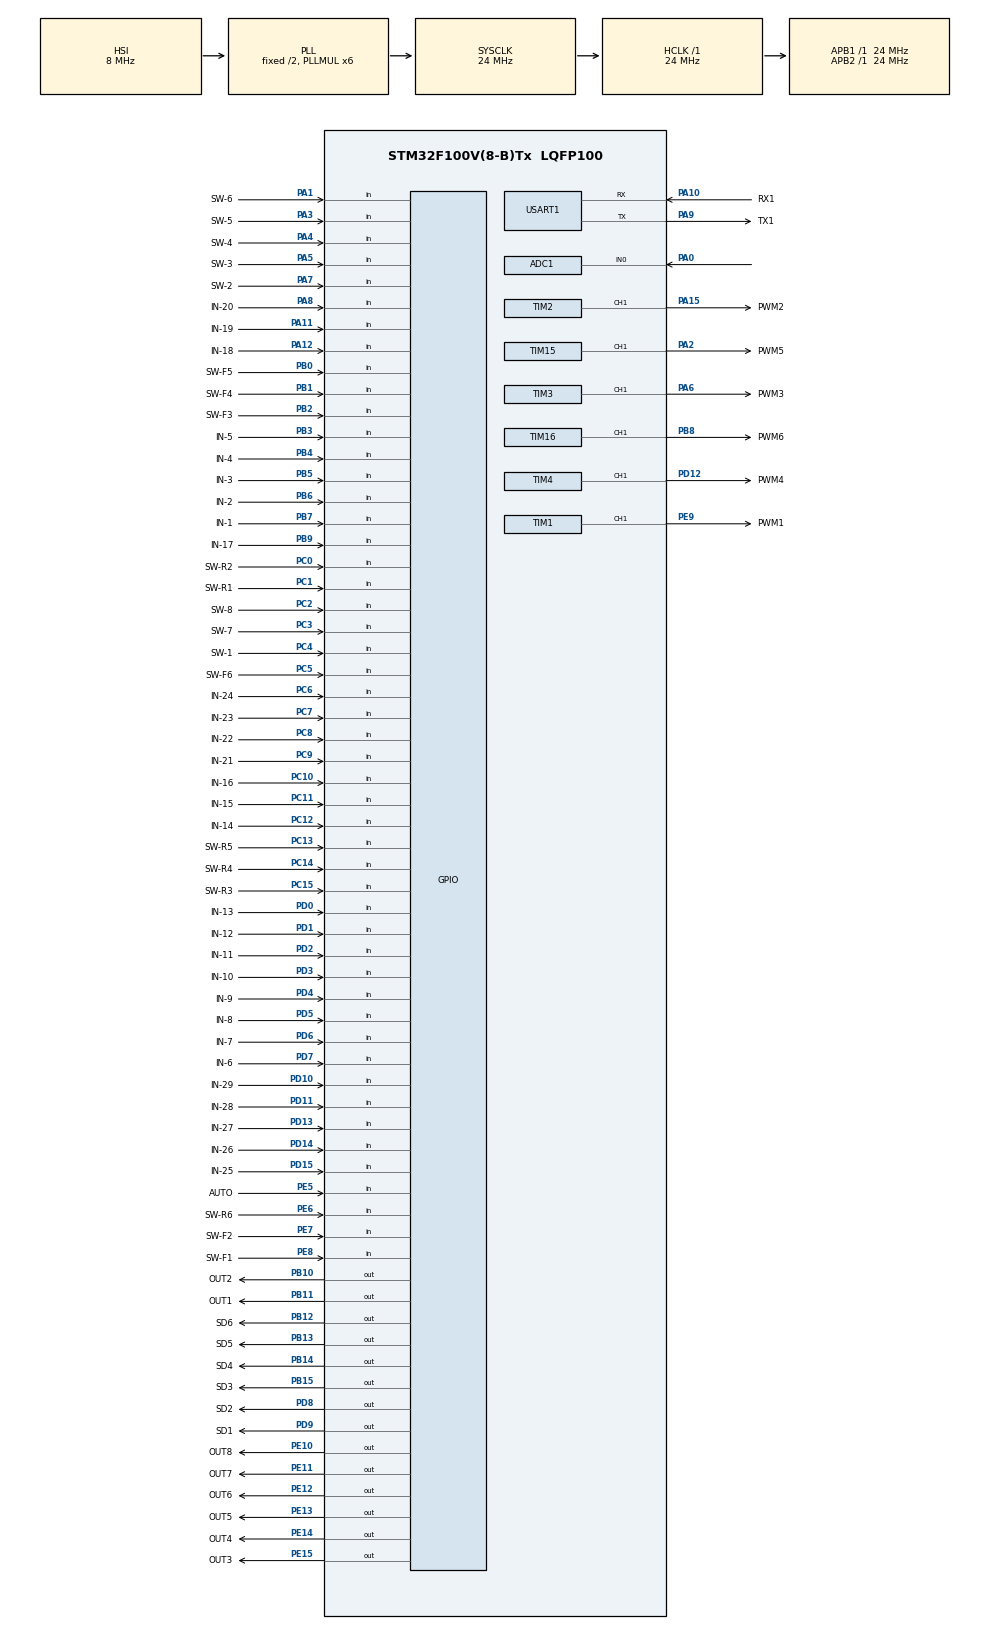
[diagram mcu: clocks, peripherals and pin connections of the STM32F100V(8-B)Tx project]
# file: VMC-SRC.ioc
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ADC1.Channel-0\#ChannelRegularConversion=ADC_CHANNEL_0
ADC1.NbrOfConversionFlag=1
ADC1.Rank-0\#ChannelRegularConversion=1
ADC1.SamplingTime-0\#ChannelRegularConversion=ADC_SAMPLETIME_1CYCLE_5
ADC1.master=1
Mcu.Family=STM32F1
Mcu.Name=STM32F100V(8-B)Tx
Mcu.Package=LQFP100
NVIC.PriorityGroup=NVIC_PRIORITYGROUP_4
NVIC.USART1_IRQn=true\:0\:0\:false\:false\:true\:true
PA0-WKUP.Signal=ADCx_IN0
PA1.GPIO_Label=SW-6
PA1.Signal=GPIO_Input
PA10.GPIO_Label=RX1
PA10.Mode=Asynchronous
PA10.Signal=USART1_RX
PA11.GPIO_Label=IN-19
PA11.Signal=GPIO_Input
PA12.GPIO_Label=IN-18
PA12.Signal=GPIO_Input
PA13.Mode=Serial_Wire
PA13.Signal=SYS_JTMS-SWDIO
PA14.Mode=Serial_Wire
PA14.Signal=SYS_JTCK-SWCLK
PA15.GPIO_Label=PWM2
PA15.Signal=S_TIM2_CH1_ETR
PA2.GPIO_Label=PWM5
PA2.Signal=S_TIM15_CH1
PA3.GPIO_Label=SW-5
PA3.Signal=GPIO_Input
PA4.GPIO_Label=SW-4
PA4.Signal=GPIO_Input
PA5.GPIO_Label=SW-3
PA5.Signal=GPIO_Input
PA6.GPIO_Label=PWM3
PA6.Signal=S_TIM3_CH1
PA7.GPIO_Label=SW-2
PA7.Signal=GPIO_Input
PA8.GPIO_Label=IN-20
PA8.Signal=GPIO_Input
PA9.GPIO_Label=TX1
PA9.Mode=Asynchronous
PA9.Signal=USART1_TX
PB0.GPIO_Label=SW-F5
PB0.Signal=GPIO_Input
PB1.GPIO_Label=SW-F4
PB1.Signal=GPIO_Input
PB10.GPIO_Label=OUT2
PB10.Signal=GPIO_Output
PB11.GPIO_Label=OUT1
PB11.Signal=GPIO_Output
PB12.GPIO_Label=SD6
PB12.Signal=GPIO_Output
PB13.GPIO_Label=SD5
PB13.Signal=GPIO_Output
PB14.GPIO_Label=SD4
PB14.Signal=GPIO_Output
PB15.GPIO_Label=SD3
PB15.Signal=GPIO_Output
PB2.GPIO_Label=SW-F3
PB2.Signal=GPIO_Input
PB3.GPIO_Label=IN-5
PB3.Signal=GPIO_Input
PB4.GPIO_Label=IN-4
PB4.Signal=GPIO_Input
PB5.GPIO_Label=IN-3
PB5.Signal=GPIO_Input
PB6.GPIO_Label=IN-2
PB6.Signal=GPIO_Input
PB7.GPIO_Label=IN-1
PB7.Signal=GPIO_Input
PB8.GPIO_Label=PWM6
PB8.Signal=S_TIM16_CH1
PB9.GPIO_Label=IN-17
PB9.Signal=GPIO_Input
PC0.GPIO_Label=SW-R2
PC0.Signal=GPIO_Input
PC1.GPIO_Label=SW-R1
PC1.Signal=GPIO_Input
PC10.GPIO_Label=IN-16
PC10.Signal=GPIO_Input
PC11.GPIO_Label=IN-15
PC11.Signal=GPIO_Input
PC12.GPIO_Label=IN-14
PC12.Signal=GPIO_Input
PC13-TAMPER-RTC.GPIO_Label=SW-R5
PC13-TAMPER-RTC.Signal=GPIO_Input
PC14-OSC32_IN.GPIO_Label=SW-R4
PC14-OSC32_IN.Signal=GPIO_Input
PC15-OSC32_OUT.GPIO_Label=SW-R3
PC15-OSC32_OUT.Signal=GPIO_Input
PC2.GPIO_Label=SW-8
PC2.Signal=GPIO_Input
PC3.GPIO_Label=SW-7
PC3.Signal=GPIO_Input
PC4.GPIO_Label=SW-1
PC4.Signal=GPIO_Input
PC5.GPIO_Label=SW-F6
PC5.Signal=GPIO_Input
PC6.GPIO_Label=IN-24
PC6.Signal=GPIO_Input
PC7.GPIO_Label=IN-23
PC7.Signal=GPIO_Input
PC8.GPIO_Label=IN-22
PC8.Signal=GPIO_Input
PC9.GPIO_Label=IN-21
PC9.Signal=GPIO_Input
PD0.GPIO_Label=IN-13
PD0.Signal=GPIO_Input
PD1.GPIO_Label=IN-12
PD1.Signal=GPIO_Input
PD10.GPIO_Label=IN-29
PD10.Signal=GPIO_Input
PD11.GPIO_Label=IN-28
PD11.Signal=GPIO_Input
PD12.GPIO_Label=PWM4
PD12.Signal=S_TIM4_CH1
PD13.GPIO_Label=IN-27
PD13.Signal=GPIO_Input
PD14.GPIO_Label=IN-26
PD14.Signal=GPIO_Input
PD15.GPIO_Label=IN-25
PD15.Signal=GPIO_Input
PD2.GPIO_Label=IN-11
PD2.Signal=GPIO_Input
PD3.GPIO_Label=IN-10
PD3.Signal=GPIO_Input
PD4.GPIO_Label=IN-9
PD4.Signal=GPIO_Input
PD5.GPIO_Label=IN-8
PD5.Signal=GPIO_Input
PD6.GPIO_Label=IN-7
PD6.Signal=GPIO_Input
PD7.GPIO_Label=IN-6
PD7.Signal=GPIO_Input
PD8.GPIO_Label=SD2
PD8.Signal=GPIO_Output
PD9.GPIO_Label=SD1
PD9.Signal=GPIO_Output
PE10.GPIO_Label=OUT8
PE10.Signal=GPIO_Output
PE11.GPIO_Label=OUT7
PE11.Signal=GPIO_Output
PE12.GPIO_Label=OUT6
PE12.Signal=GPIO_Output
PE13.GPIO_Label=OUT5
PE13.Signal=GPIO_Output
PE14.GPIO_Label=OUT4
PE14.Signal=GPIO_Output
PE15.GPIO_Label=OUT3
PE15.Signal=GPIO_Output
PE5.GPIO_Label=AUTO
PE5.Signal=GPIO_Input
PE6.GPIO_Label=SW-R6
PE6.Signal=GPIO_Input
PE7.GPIO_Label=SW-F2
PE7.Signal=GPIO_Input
PE8.GPIO_Label=SW-F1
PE8.Signal=GPIO_Input
PE9.GPIO_Label=PWM1
PE9.Signal=S_TIM1_CH1
ProjectManager.HeapSize=0x200
ProjectManager.StackSize=0x400
ProjectManager.TargetToolchain=MDK-ARM V5
RCC.AHBFreq_Value=24000000
RCC.APB1Freq_Value=24000000
RCC.APB1TimFreq_Value=24000000
RCC.APB2Freq_Value=24000000
RCC.APB2TimFreq_Value=24000000
RCC.HCLKFreq_Value=24000000
RCC.PLLMUL=RCC_PLL_MUL6
RCC.SYSCLKFreq_VALUE=24000000
RCC.SYSCLKSource=RCC_SYSCLKSOURCE_PLLCLK
SH.ADCx_IN0.0=ADC1_IN0,IN0
SH.S_TIM15_CH1.0=TIM15_CH1,PWM Generation1 CH1
SH.S_TIM16_CH1.0=TIM16_CH1,PWM Generation1 CH1
SH.S_TIM1_CH1.0=TIM1_CH1,PWM Generation1 CH1
SH.S_TIM2_CH1_ETR.0=TIM2_CH1,PWM Generation1 CH1
SH.S_TIM3_CH1.0=TIM3_CH1,PWM Generation1 CH1
SH.S_TIM4_CH1.0=TIM4_CH1,PWM Generation1 CH1
TIM1.Channel-PWM\ Generation1\ CH1=TIM_CHANNEL_1
TIM1.Period=49
TIM1.Prescaler=23
TIM1.Pulse-PWM\ Generation1\ CH1=45
TIM15.Channel-PWM\ Generation1\ CH1=TIM_CHANNEL_1
TIM16.Channel=TIM_CHANNEL_1
TIM2.Channel-PWM\ Generation1\ CH1=TIM_CHANNEL_1
TIM3.Channel-PWM\ Generation1\ CH1=TIM_CHANNEL_1
TIM4.Channel-PWM\ Generation1\ CH1=TIM_CHANNEL_1
USART1.VirtualMode=VM_ASYNC
VP_TIM16_VS_ClockSourceINT.Mode=Enable_Timer
VP_TIM3_VS_ClockSourceINT.Mode=Internal
board=VMC-SRC

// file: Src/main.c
/**
  ******************************************************************************
  * @file           : main.c
  * @brief          : Main program body
  ******************************************************************************
  ** This notice applies to any and all portions of this file
  * that are not between comment pairs USER CODE BEGIN and
  * USER CODE END. Other portions of this file, whether
  * inserted by the user or by software development tools
  * are owned by their respective copyright owners.
  *
  * COPYRIGHT(c) 2018 STMicroelectronics
  *
  * Redistribution and use in source and binary forms, with or without modification,
  * are permitted provided that the following conditions are met:
  *   1. Redistributions of source code must retain the above copyright notice,
  *      this list of conditions and the following disclaimer.
  *   2. Redistributions in binary form must reproduce the above copyright notice,
  *      this list of conditions and the following disclaimer in the documentation
  *      and/or other materials provided with the distribution.
  *   3. Neither the name of STMicroelectronics nor the names of its contributors
  *      may be used to endorse or promote products derived from this software
  *      without specific prior written permission.
  *
  * THIS SOFTWARE IS PROVIDED BY THE COPYRIGHT HOLDERS AND CONTRIBUTORS "AS IS"
  * AND ANY EXPRESS OR IMPLIED WARRANTIES, INCLUDING, BUT NOT LIMITED TO, THE
  * IMPLIED WARRANTIES OF MERCHANTABILITY AND FITNESS FOR A PARTICULAR PURPOSE ARE
  * DISCLAIMED. IN NO EVENT SHALL THE COPYRIGHT HOLDER OR CONTRIBUTORS BE LIABLE
  * FOR ANY DIRECT, INDIRECT, INCIDENTAL, SPECIAL, EXEMPLARY, OR CONSEQUENTIAL
  * DAMAGES (INCLUDING, BUT NOT LIMITED TO, PROCUREMENT OF SUBSTITUTE GOODS OR
  * SERVICES; LOSS OF USE, DATA, OR PROFITS; OR BUSINESS INTERRUPTION) HOWEVER
  * CAUSED AND ON ANY THEORY OF LIABILITY, WHETHER IN CONTRACT, STRICT LIABILITY,
  * OR TORT (INCLUDING NEGLIGENCE OR OTHERWISE) ARISING IN ANY WAY OUT OF THE USE
  * OF THIS SOFTWARE, EVEN IF ADVISED OF THE POSSIBILITY OF SUCH DAMAGE.
  *
  ******************************************************************************
  */
#include "main.h"
#include "stm32f1xx_hal.h"

/* USER CODE BEGIN Includes */
#include "C:\Users\TheVeganElectrolance\Documents\Electrolance Company\Projects\04042018-JAAVIN-VMC\VMC-SRC\MDK-ARM\appGPIO.h"
/* USER CODE END Includes */

ADC_HandleTypeDef hadc1;

TIM_HandleTypeDef htim1;
TIM_HandleTypeDef htim2;
TIM_HandleTypeDef htim3;
TIM_HandleTypeDef htim4;
TIM_HandleTypeDef htim15;
TIM_HandleTypeDef htim16;

UART_HandleTypeDef huart1;

/* USER CODE BEGIN PV */
/* Private variables ---------------------------------------------------------*/
extern void (* fparr[8]) ();
uint32_t  manualSWV =0xFFFFFFFF;
uint8_t buffer[30];
uint8_t data;
uint8_t indexA = 0;
uint8_t final_pos = 0;
_Bool processData = 0;
//extern void readmanualSW();
//extern void trigmanualSW();
/* USER CODE END PV */

void SystemClock_Config(void);
static void MX_GPIO_Init(void);
static void MX_ADC1_Init(void);
static void MX_TIM1_Init(void);
static void MX_TIM2_Init(void);
static void MX_TIM3_Init(void);
static void MX_TIM4_Init(void);
static void MX_TIM15_Init(void);
static void MX_TIM16_Init(void);
static void MX_USART1_UART_Init(void);

void HAL_TIM_MspPostInit(TIM_HandleTypeDef *htim);

/* USER CODE BEGIN PFP */
/* Private function prototypes -----------------------------------------------*/

/* USER CODE END PFP */

int main(void)
{
  /* USER CODE BEGIN 1 */
	indexA = 0x00;
  /* USER CODE END 1 */

  /* MCU Configuration----------------------------------------------------------*/

  /* Reset of all peripherals, Initializes the Flash interface and the Systick. */
  HAL_Init();

  /* Configure the system clock */
  SystemClock_Config();

  /* Initialize all configured peripherals */
  MX_GPIO_Init();
  MX_ADC1_Init();
  MX_TIM1_Init();
  MX_TIM2_Init();
  MX_TIM3_Init();
  MX_TIM4_Init();
  MX_TIM15_Init();
  MX_TIM16_Init();
  MX_USART1_UART_Init();
  /* USER CODE BEGIN 2 */
	_Bool Auto = 0x00;
	_Bool autoButton;
	__HAL_UART_ENABLE_IT(&huart1, UART_IT_RXNE);
	HAL_UART_Receive_IT(&huart1,&data, 1);// enable UART interupt
  /* USER CODE END 2 */

  /* Infinite loop */
  /* USER CODE BEGIN WHILE */
  while (1)
  {

		autoButton = HAL_GPIO_ReadPin(AUTO_GPIO_Port,AUTO_Pin);
		if(HAL_GPIO_ReadPin(AUTO_GPIO_Port,AUTO_Pin))
		{
			Auto = 0x01;
		}
		else
		{
			Auto = 0x00;
			//Read all the switch
			readmanualSW();
			//Trigger Function.
			trigmanualSW();
		}

		//HAL_GPIO_TogglePin(OUT1_GPIO_Port,OUT1_Pin);
		//HAL_Delay(1000);
		//RELAY8_ON();
		HAL_Delay(1000);
		//RELAY8_OFF();
		//HAL_GPIO_WritePin(OUT1_GPIO_Port,OUT1_Pin, GPIO_PIN_SET
  /* USER CODE END WHILE */

  /* USER CODE BEGIN 3 */

//			for(uint8_t x =0; x<16;x++)
//      {
//				(*fparr[x])();
//				HAL_Delay(500);
//      }

		if(processData)
		{
			// DO all the check.
			processData = 0;
			//on the interupt receive
			switch (buffer[3])
      {
      	case 0x23: //relay turn
					if((buffer[4] + buffer[5]) == (uint8_t) 0x01) // Relay 1 OFF
						RELAY1_OFF();
					else if ((buffer[4] + buffer[5]) == (uint8_t)0x02)
					{
						RELAY1_ON();
					}

					if((buffer[4] + buffer[5]) == (uint8_t) 0x02) // Relay 2 OFF
						RELAY2_OFF();
					else if ((buffer[4] + buffer[5]) == (uint8_t)0x03)
					{
						RELAY2_ON();
					}

					if((buffer[4] + buffer[5]) == (uint8_t) 0x03) // Relay 3 OFF
						RELAY3_OFF();
					else if ((buffer[4] + buffer[5]) == (uint8_t)0x04)
					{
						RELAY3_ON();
					}

					if((buffer[4] + buffer[5]) == (uint8_t) 0x04) // Relay 4 OFF
						RELAY4_OFF();
					else if ((buffer[4] + buffer[5]) == (uint8_t)0x05)
					{
						RELAY4_ON();
					}

					if((buffer[4] + buffer[5]) == (uint8_t) 0x05) // Relay 5 OFF
						RELAY5_OFF();
					else if ((buffer[4] + buffer[5]) == (uint8_t)0x06)
					{
						RELAY5_ON();
					}

					if((buffer[4] + buffer[5]) == (uint8_t) 0x06) // Relay 6 OFF
						RELAY6_OFF();
					else if ((buffer[4] + buffer[5]) == (uint8_t)0x07)
					{
						RELAY6_ON();
					}

					if((buffer[4] + buffer[5]) == (uint8_t) 0x07) // Relay 7 OFF
						RELAY7_OFF();
					else if ((buffer[4] + buffer[5]) == (uint8_t)0x08)
					{
						RELAY7_ON();
					}

					if((buffer[4] + buffer[5]) == (uint8_t) 0x08) // Relay 8 OFF
						RELAY8_OFF();
					else if ((buffer[4] + buffer[5]) == (uint8_t)0x09)
					{
						RELAY8_ON();
					}

					HAL_UART_Receive_IT(&huart1,&data, 1);
      		break;
      	//case:
      		//break;
      	default:
					//HAL_UART_Receive_IT(&huart1,&data, 1);
      		break;

      }
		}

	}
  /* USER CODE END 3 */

}

void SystemClock_Config(void)
{

  RCC_OscInitTypeDef RCC_OscInitStruct;
  RCC_ClkInitTypeDef RCC_ClkInitStruct;
  RCC_PeriphCLKInitTypeDef PeriphClkInit;

    /**Initializes the CPU, AHB and APB busses clocks
    */
  RCC_OscInitStruct.OscillatorType = RCC_OSCILLATORTYPE_HSI;
  RCC_OscInitStruct.HSIState = RCC_HSI_ON;
  RCC_OscInitStruct.HSICalibrationValue = 16;
  RCC_OscInitStruct.PLL.PLLState = RCC_PLL_ON;
  RCC_OscInitStruct.PLL.PLLSource = RCC_PLLSOURCE_HSI_DIV2;
  RCC_OscInitStruct.PLL.PLLMUL = RCC_PLL_MUL6;
  if (HAL_RCC_OscConfig(&RCC_OscInitStruct) != HAL_OK)
  {
    _Error_Handler(__FILE__, __LINE__);
  }

    /**Initializes the CPU, AHB and APB busses clocks
    */
  RCC_ClkInitStruct.ClockType = RCC_CLOCKTYPE_HCLK|RCC_CLOCKTYPE_SYSCLK
                              |RCC_CLOCKTYPE_PCLK1|RCC_CLOCKTYPE_PCLK2;
  RCC_ClkInitStruct.SYSCLKSource = RCC_SYSCLKSOURCE_PLLCLK;
  RCC_ClkInitStruct.AHBCLKDivider = RCC_SYSCLK_DIV1;
  RCC_ClkInitStruct.APB1CLKDivider = RCC_HCLK_DIV1;
  RCC_ClkInitStruct.APB2CLKDivider = RCC_HCLK_DIV1;

  if (HAL_RCC_ClockConfig(&RCC_ClkInitStruct, FLASH_LATENCY_0) != HAL_OK)
  {
    _Error_Handler(__FILE__, __LINE__);
  }

  PeriphClkInit.PeriphClockSelection = RCC_PERIPHCLK_ADC;
  PeriphClkInit.AdcClockSelection = RCC_ADCPCLK2_DIV2;
  if (HAL_RCCEx_PeriphCLKConfig(&PeriphClkInit) != HAL_OK)
  {
    _Error_Handler(__FILE__, __LINE__);
  }

    /**Configure the Systick interrupt time
    */
  HAL_SYSTICK_Config(HAL_RCC_GetHCLKFreq()/1000);

    /**Configure the Systick
    */
  HAL_SYSTICK_CLKSourceConfig(SYSTICK_CLKSOURCE_HCLK);

  /* SysTick_IRQn interrupt configuration */
  HAL_NVIC_SetPriority(SysTick_IRQn, 0, 0);
}

/* ADC1 init function */
static void MX_ADC1_Init(void)
{

  ADC_ChannelConfTypeDef sConfig;

    /**Common config
    */
  hadc1.Instance = ADC1;
  hadc1.Init.ScanConvMode = ADC_SCAN_DISABLE;
  hadc1.Init.ContinuousConvMode = DISABLE;
  hadc1.Init.DiscontinuousConvMode = DISABLE;
  hadc1.Init.ExternalTrigConv = ADC_SOFTWARE_START;
  hadc1.Init.DataAlign = ADC_DATAALIGN_RIGHT;
  hadc1.Init.NbrOfConversion = 1;
  if (HAL_ADC_Init(&hadc1) != HAL_OK)
  {
    _Error_Handler(__FILE__, __LINE__);
  }

    /**Configure Regular Channel
    */
  sConfig.Channel = ADC_CHANNEL_0;
  sConfig.Rank = ADC_REGULAR_RANK_1;
  sConfig.SamplingTime = ADC_SAMPLETIME_1CYCLE_5;
  if (HAL_ADC_ConfigChannel(&hadc1, &sConfig) != HAL_OK)
  {
    _Error_Handler(__FILE__, __LINE__);
  }

}

/* TIM1 init function */
static void MX_TIM1_Init(void)
{

  TIM_MasterConfigTypeDef sMasterConfig;
  TIM_OC_InitTypeDef sConfigOC;
  TIM_BreakDeadTimeConfigTypeDef sBreakDeadTimeConfig;

  htim1.Instance = TIM1;
  htim1.Init.Prescaler = 23;
  htim1.Init.CounterMode = TIM_COUNTERMODE_UP;
  htim1.Init.Period = 49;
  htim1.Init.ClockDivision = TIM_CLOCKDIVISION_DIV1;
  htim1.Init.RepetitionCounter = 0;
  htim1.Init.AutoReloadPreload = TIM_AUTORELOAD_PRELOAD_DISABLE;
  if (HAL_TIM_PWM_Init(&htim1) != HAL_OK)
  {
    _Error_Handler(__FILE__, __LINE__);
  }

  sMasterConfig.MasterOutputTrigger = TIM_TRGO_RESET;
  sMasterConfig.MasterSlaveMode = TIM_MASTERSLAVEMODE_DISABLE;
  if (HAL_TIMEx_MasterConfigSynchronization(&htim1, &sMasterConfig) != HAL_OK)
  {
    _Error_Handler(__FILE__, __LINE__);
  }

  sConfigOC.OCMode = TIM_OCMODE_PWM1;
  sConfigOC.Pulse = 45;
  sConfigOC.OCPolarity = TIM_OCPOLARITY_HIGH;
  sConfigOC.OCNPolarity = TIM_OCNPOLARITY_HIGH;
  sConfigOC.OCFastMode = TIM_OCFAST_DISABLE;
  sConfigOC.OCIdleState = TIM_OCIDLESTATE_RESET;
  sConfigOC.OCNIdleState = TIM_OCNIDLESTATE_RESET;
  if (HAL_TIM_PWM_ConfigChannel(&htim1, &sConfigOC, TIM_CHANNEL_1) != HAL_OK)
  {
    _Error_Handler(__FILE__, __LINE__);
  }

  sBreakDeadTimeConfig.OffStateRunMode = TIM_OSSR_DISABLE;
  sBreakDeadTimeConfig.OffStateIDLEMode = TIM_OSSI_DISABLE;
  sBreakDeadTimeConfig.LockLevel = TIM_LOCKLEVEL_OFF;
  sBreakDeadTimeConfig.DeadTime = 0;
  sBreakDeadTimeConfig.BreakState = TIM_BREAK_DISABLE;
  sBreakDeadTimeConfig.BreakPolarity = TIM_BREAKPOLARITY_HIGH;
  sBreakDeadTimeConfig.AutomaticOutput = TIM_AUTOMATICOUTPUT_DISABLE;
  if (HAL_TIMEx_ConfigBreakDeadTime(&htim1, &sBreakDeadTimeConfig) != HAL_OK)
  {
    _Error_Handler(__FILE__, __LINE__);
  }

  HAL_TIM_MspPostInit(&htim1);

}

/* TIM2 init function */
static void MX_TIM2_Init(void)
{

  TIM_MasterConfigTypeDef sMasterConfig;
  TIM_OC_InitTypeDef sConfigOC;

  htim2.Instance = TIM2;
  htim2.Init.Prescaler = 0;
  htim2.Init.CounterMode = TIM_COUNTERMODE_UP;
  htim2.Init.Period = 0;
  htim2.Init.ClockDivision = TIM_CLOCKDIVISION_DIV1;
  htim2.Init.AutoReloadPreload = TIM_AUTORELOAD_PRELOAD_DISABLE;
  if (HAL_TIM_PWM_Init(&htim2) != HAL_OK)
  {
    _Error_Handler(__FILE__, __LINE__);
  }

  sMasterConfig.MasterOutputTrigger = TIM_TRGO_RESET;
  sMasterConfig.MasterSlaveMode = TIM_MASTERSLAVEMODE_DISABLE;
  if (HAL_TIMEx_MasterConfigSynchronization(&htim2, &sMasterConfig) != HAL_OK)
  {
    _Error_Handler(__FILE__, __LINE__);
  }

  sConfigOC.OCMode = TIM_OCMODE_PWM1;
  sConfigOC.Pulse = 0;
  sConfigOC.OCPolarity = TIM_OCPOLARITY_HIGH;
  sConfigOC.OCFastMode = TIM_OCFAST_DISABLE;
  if (HAL_TIM_PWM_ConfigChannel(&htim2, &sConfigOC, TIM_CHANNEL_1) != HAL_OK)
  {
    _Error_Handler(__FILE__, __LINE__);
  }

  HAL_TIM_MspPostInit(&htim2);

}

/* TIM3 init function */
static void MX_TIM3_Init(void)
{

  TIM_ClockConfigTypeDef sClockSourceConfig;
  TIM_MasterConfigTypeDef sMasterConfig;
  TIM_OC_InitTypeDef sConfigOC;

  htim3.Instance = TIM3;
  htim3.Init.Prescaler = 0;
  htim3.Init.CounterMode = TIM_COUNTERMODE_UP;
  htim3.Init.Period = 0;
  htim3.Init.ClockDivision = TIM_CLOCKDIVISION_DIV1;
  htim3.Init.AutoReloadPreload = TIM_AUTORELOAD_PRELOAD_DISABLE;
  if (HAL_TIM_Base_Init(&htim3) != HAL_OK)
  {
    _Error_Handler(__FILE__, __LINE__);
  }

  sClockSourceConfig.ClockSource = TIM_CLOCKSOURCE_INTERNAL;
  if (HAL_TIM_ConfigClockSource(&htim3, &sClockSourceConfig) != HAL_OK)
  {
    _Error_Handler(__FILE__, __LINE__);
  }

  if (HAL_TIM_PWM_Init(&htim3) != HAL_OK)
  {
    _Error_Handler(__FILE__, __LINE__);
  }

  sMasterConfig.MasterOutputTrigger = TIM_TRGO_RESET;
  sMasterConfig.MasterSlaveMode = TIM_MASTERSLAVEMODE_DISABLE;
  if (HAL_TIMEx_MasterConfigSynchronization(&htim3, &sMasterConfig) != HAL_OK)
  {
    _Error_Handler(__FILE__, __LINE__);
  }

  sConfigOC.OCMode = TIM_OCMODE_PWM1;
  sConfigOC.Pulse = 0;
  sConfigOC.OCPolarity = TIM_OCPOLARITY_HIGH;
  sConfigOC.OCFastMode = TIM_OCFAST_DISABLE;
  if (HAL_TIM_PWM_ConfigChannel(&htim3, &sConfigOC, TIM_CHANNEL_1) != HAL_OK)
  {
    _Error_Handler(__FILE__, __LINE__);
  }

  HAL_TIM_MspPostInit(&htim3);

}

/* TIM4 init function */
static void MX_TIM4_Init(void)
{

  TIM_MasterConfigTypeDef sMasterConfig;
  TIM_OC_InitTypeDef sConfigOC;

  htim4.Instance = TIM4;
  htim4.Init.Prescaler = 0;
  htim4.Init.CounterMode = TIM_COUNTERMODE_UP;
  htim4.Init.Period = 0;
  htim4.Init.ClockDivision = TIM_CLOCKDIVISION_DIV1;
  htim4.Init.AutoReloadPreload = TIM_AUTORELOAD_PRELOAD_DISABLE;
  if (HAL_TIM_PWM_Init(&htim4) != HAL_OK)
  {
    _Error_Handler(__FILE__, __LINE__);
  }

  sMasterConfig.MasterOutputTrigger = TIM_TRGO_RESET;
  sMasterConfig.MasterSlaveMode = TIM_MASTERSLAVEMODE_DISABLE;
  if (HAL_TIMEx_MasterConfigSynchronization(&htim4, &sMasterConfig) != HAL_OK)
  {
    _Error_Handler(__FILE__, __LINE__);
  }

  sConfigOC.OCMode = TIM_OCMODE_PWM1;
  sConfigOC.Pulse = 0;
  sConfigOC.OCPolarity = TIM_OCPOLARITY_HIGH;
  sConfigOC.OCFastMode = TIM_OCFAST_DISABLE;
  if (HAL_TIM_PWM_ConfigChannel(&htim4, &sConfigOC, TIM_CHANNEL_1) != HAL_OK)
  {
    _Error_Handler(__FILE__, __LINE__);
  }

  HAL_TIM_MspPostInit(&htim4);

}

/* TIM15 init function */
static void MX_TIM15_Init(void)
{

  TIM_MasterConfigTypeDef sMasterConfig;
  TIM_OC_InitTypeDef sConfigOC;
  TIM_BreakDeadTimeConfigTypeDef sBreakDeadTimeConfig;

  htim15.Instance = TIM15;
  htim15.Init.Prescaler = 0;
  htim15.Init.CounterMode = TIM_COUNTERMODE_UP;
  htim15.Init.Period = 0;
  htim15.Init.ClockDivision = TIM_CLOCKDIVISION_DIV1;
  htim15.Init.RepetitionCounter = 0;
  htim15.Init.AutoReloadPreload = TIM_AUTORELOAD_PRELOAD_DISABLE;
  if (HAL_TIM_PWM_Init(&htim15) != HAL_OK)
  {
    _Error_Handler(__FILE__, __LINE__);
  }

  sMasterConfig.MasterOutputTrigger = TIM_TRGO_RESET;
  sMasterConfig.MasterSlaveMode = TIM_MASTERSLAVEMODE_DISABLE;
  if (HAL_TIMEx_MasterConfigSynchronization(&htim15, &sMasterConfig) != HAL_OK)
  {
    _Error_Handler(__FILE__, __LINE__);
  }

  sConfigOC.OCMode = TIM_OCMODE_PWM1;
  sConfigOC.Pulse = 0;
  sConfigOC.OCPolarity = TIM_OCPOLARITY_HIGH;
  sConfigOC.OCNPolarity = TIM_OCNPOLARITY_HIGH;
  sConfigOC.OCFastMode = TIM_OCFAST_DISABLE;
  sConfigOC.OCIdleState = TIM_OCIDLESTATE_RESET;
  sConfigOC.OCNIdleState = TIM_OCNIDLESTATE_RESET;
  if (HAL_TIM_PWM_ConfigChannel(&htim15, &sConfigOC, TIM_CHANNEL_1) != HAL_OK)
  {
    _Error_Handler(__FILE__, __LINE__);
  }

  sBreakDeadTimeConfig.OffStateRunMode = TIM_OSSR_DISABLE;
  sBreakDeadTimeConfig.OffStateIDLEMode = TIM_OSSI_DISABLE;
  sBreakDeadTimeConfig.LockLevel = TIM_LOCKLEVEL_OFF;
  sBreakDeadTimeConfig.DeadTime = 0;
  sBreakDeadTimeConfig.BreakState = TIM_BREAK_DISABLE;
  sBreakDeadTimeConfig.BreakPolarity = TIM_BREAKPOLARITY_HIGH;
  sBreakDeadTimeConfig.AutomaticOutput = TIM_AUTOMATICOUTPUT_DISABLE;
  if (HAL_TIMEx_ConfigBreakDeadTime(&htim15, &sBreakDeadTimeConfig) != HAL_OK)
  {
    _Error_Handler(__FILE__, __LINE__);
  }

  HAL_TIM_MspPostInit(&htim15);

}

/* TIM16 init function */
static void MX_TIM16_Init(void)
{

  TIM_OC_InitTypeDef sConfigOC;
  TIM_BreakDeadTimeConfigTypeDef sBreakDeadTimeConfig;

  htim16.Instance = TIM16;
  htim16.Init.Prescaler = 0;
  htim16.Init.CounterMode = TIM_COUNTERMODE_UP;
  htim16.Init.Period = 0;
  htim16.Init.ClockDivision = TIM_CLOCKDIVISION_DIV1;
  htim16.Init.RepetitionCounter = 0;
  htim16.Init.AutoReloadPreload = TIM_AUTORELOAD_PRELOAD_DISABLE;
  if (HAL_TIM_Base_Init(&htim16) != HAL_OK)
  {
    _Error_Handler(__FILE__, __LINE__);
  }

  if (HAL_TIM_PWM_Init(&htim16) != HAL_OK)
  {
    _Error_Handler(__FILE__, __LINE__);
  }

  sConfigOC.OCMode = TIM_OCMODE_PWM1;
  sConfigOC.Pulse = 0;
  sConfigOC.OCPolarity = TIM_OCPOLARITY_HIGH;
  sConfigOC.OCNPolarity = TIM_OCNPOLARITY_HIGH;
  sConfigOC.OCFastMode = TIM_OCFAST_DISABLE;
  sConfigOC.OCIdleState = TIM_OCIDLESTATE_RESET;
  sConfigOC.OCNIdleState = TIM_OCNIDLESTATE_RESET;
  if (HAL_TIM_PWM_ConfigChannel(&htim16, &sConfigOC, TIM_CHANNEL_1) != HAL_OK)
  {
    _Error_Handler(__FILE__, __LINE__);
  }

  sBreakDeadTimeConfig.OffStateRunMode = TIM_OSSR_DISABLE;
  sBreakDeadTimeConfig.OffStateIDLEMode = TIM_OSSI_DISABLE;
  sBreakDeadTimeConfig.LockLevel = TIM_LOCKLEVEL_OFF;
  sBreakDeadTimeConfig.DeadTime = 0;
  sBreakDeadTimeConfig.BreakState = TIM_BREAK_DISABLE;
  sBreakDeadTimeConfig.BreakPolarity = TIM_BREAKPOLARITY_HIGH;
  sBreakDeadTimeConfig.AutomaticOutput = TIM_AUTOMATICOUTPUT_DISABLE;
  if (HAL_TIMEx_ConfigBreakDeadTime(&htim16, &sBreakDeadTimeConfig) != HAL_OK)
  {
    _Error_Handler(__FILE__, __LINE__);
  }

  HAL_TIM_MspPostInit(&htim16);

}

/* USART1 init function */
static void MX_USART1_UART_Init(void)
{

  huart1.Instance = USART1;
  huart1.Init.BaudRate = 115200;
  huart1.Init.WordLength = UART_WORDLENGTH_8B;
  huart1.Init.StopBits = UART_STOPBITS_1;
  huart1.Init.Parity = UART_PARITY_NONE;
  huart1.Init.Mode = UART_MODE_TX_RX;
  huart1.Init.HwFlowCtl = UART_HWCONTROL_NONE;
  huart1.Init.OverSampling = UART_OVERSAMPLING_16;
  if (HAL_UART_Init(&huart1) != HAL_OK)
  {
    _Error_Handler(__FILE__, __LINE__);
  }

}

/** Configure pins as
        * Analog
        * Input
        * Output
        * EVENT_OUT
        * EXTI
*/
static void MX_GPIO_Init(void)
{

  GPIO_InitTypeDef GPIO_InitStruct;

  /* GPIO Ports Clock Enable */
  __HAL_RCC_GPIOE_CLK_ENABLE();
  __HAL_RCC_GPIOC_CLK_ENABLE();
  __HAL_RCC_GPIOA_CLK_ENABLE();
  __HAL_RCC_GPIOB_CLK_ENABLE();
  __HAL_RCC_GPIOD_CLK_ENABLE();

  /*Configure GPIO pin Output Level */
  HAL_GPIO_WritePin(GPIOE, OUT8_Pin|OUT7_Pin|OUT6_Pin|OUT5_Pin
                          |OUT4_Pin|OUT3_Pin, GPIO_PIN_RESET);

  /*Configure GPIO pin Output Level */
  HAL_GPIO_WritePin(GPIOB, OUT2_Pin|OUT1_Pin|SD6_Pin|SD5_Pin
                          |SD4_Pin|SD3_Pin, GPIO_PIN_RESET);

  /*Configure GPIO pin Output Level */
  HAL_GPIO_WritePin(GPIOD, SD2_Pin|SD1_Pin, GPIO_PIN_RESET);

  /*Configure GPIO pins : AUTO_Pin SW_R6_Pin SW_F2_Pin SW_F1_Pin */
  GPIO_InitStruct.Pin = AUTO_Pin|SW_R6_Pin|SW_F2_Pin|SW_F1_Pin;
  GPIO_InitStruct.Mode = GPIO_MODE_INPUT;
  GPIO_InitStruct.Pull = GPIO_NOPULL;
  HAL_GPIO_Init(GPIOE, &GPIO_InitStruct);

  /*Configure GPIO pins : SW_R5_Pin SW_R4_Pin SW_R3_Pin SW_R2_Pin
                           SW_R1_Pin SW_8_Pin SW_7_Pin SW_1_Pin
                           SW_F6_Pin IN_24_Pin IN_23_Pin IN_22_Pin
                           IN_21_Pin IN_16_Pin IN_15_Pin IN_14_Pin */
  GPIO_InitStruct.Pin = SW_R5_Pin|SW_R4_Pin|SW_R3_Pin|SW_R2_Pin
                          |SW_R1_Pin|SW_8_Pin|SW_7_Pin|SW_1_Pin
                          |SW_F6_Pin|IN_24_Pin|IN_23_Pin|IN_22_Pin
                          |IN_21_Pin|IN_16_Pin|IN_15_Pin|IN_14_Pin;
  GPIO_InitStruct.Mode = GPIO_MODE_INPUT;
  GPIO_InitStruct.Pull = GPIO_NOPULL;
  HAL_GPIO_Init(GPIOC, &GPIO_InitStruct);

  /*Configure GPIO pins : SW_6_Pin SW_5_Pin SW_4_Pin SW_3_Pin
                           SW_2_Pin IN_20_Pin IN_19_Pin IN_18_Pin */
  GPIO_InitStruct.Pin = SW_6_Pin|SW_5_Pin|SW_4_Pin|SW_3_Pin
                          |SW_2_Pin|IN_20_Pin|IN_19_Pin|IN_18_Pin;
  GPIO_InitStruct.Mode = GPIO_MODE_INPUT;
  GPIO_InitStruct.Pull = GPIO_NOPULL;
  HAL_GPIO_Init(GPIOA, &GPIO_InitStruct);

  /*Configure GPIO pins : SW_F5_Pin SW_F4_Pin SW_F3_Pin IN_5_Pin
                           IN_4_Pin IN_3_Pin IN_2_Pin IN_1_Pin
                           IN_17_Pin */
  GPIO_InitStruct.Pin = SW_F5_Pin|SW_F4_Pin|SW_F3_Pin|IN_5_Pin
                          |IN_4_Pin|IN_3_Pin|IN_2_Pin|IN_1_Pin
                          |IN_17_Pin;
  GPIO_InitStruct.Mode = GPIO_MODE_INPUT;
  GPIO_InitStruct.Pull = GPIO_NOPULL;
  HAL_GPIO_Init(GPIOB, &GPIO_InitStruct);

  /*Configure GPIO pins : OUT8_Pin OUT7_Pin OUT6_Pin OUT5_Pin
                           OUT4_Pin OUT3_Pin */
  GPIO_InitStruct.Pin = OUT8_Pin|OUT7_Pin|OUT6_Pin|OUT5_Pin
                          |OUT4_Pin|OUT3_Pin;
  GPIO_InitStruct.Mode = GPIO_MODE_OUTPUT_PP;
  GPIO_InitStruct.Speed = GPIO_SPEED_FREQ_LOW;
  HAL_GPIO_Init(GPIOE, &GPIO_InitStruct);

  /*Configure GPIO pins : OUT2_Pin OUT1_Pin SD6_Pin SD5_Pin
                           SD4_Pin SD3_Pin */
  GPIO_InitStruct.Pin = OUT2_Pin|OUT1_Pin|SD6_Pin|SD5_Pin
                          |SD4_Pin|SD3_Pin;
  GPIO_InitStruct.Mode = GPIO_MODE_OUTPUT_PP;
  GPIO_InitStruct.Speed = GPIO_SPEED_FREQ_LOW;
  HAL_GPIO_Init(GPIOB, &GPIO_InitStruct);

  /*Configure GPIO pins : SD2_Pin SD1_Pin */
  GPIO_InitStruct.Pin = SD2_Pin|SD1_Pin;
  GPIO_InitStruct.Mode = GPIO_MODE_OUTPUT_PP;
  GPIO_InitStruct.Speed = GPIO_SPEED_FREQ_LOW;
  HAL_GPIO_Init(GPIOD, &GPIO_InitStruct);

  /*Configure GPIO pins : IN_29_Pin IN_28_Pin IN_27_Pin IN_26_Pin
                           IN_25_Pin IN_13_Pin IN_12_Pin IN_11_Pin
                           IN_10_Pin IN_9_Pin IN_8_Pin IN_7_Pin
                           IN_6_Pin */
  GPIO_InitStruct.Pin = IN_29_Pin|IN_28_Pin|IN_27_Pin|IN_26_Pin
                          |IN_25_Pin|IN_13_Pin|IN_12_Pin|IN_11_Pin
                          |IN_10_Pin|IN_9_Pin|IN_8_Pin|IN_7_Pin
                          |IN_6_Pin;
  GPIO_InitStruct.Mode = GPIO_MODE_INPUT;
  GPIO_InitStruct.Pull = GPIO_NOPULL;
  HAL_GPIO_Init(GPIOD, &GPIO_InitStruct);

}

/* USER CODE BEGIN 4 */
void HAL_UART_RxCpltCallback(UART_HandleTypeDef *huart)
{

		if ((indexA-1) == 0 && data != 0xAA) //if first data not AA RESET it
			{
			indexA = 0;
			}
		if(data != 0xDD)
		{
			buffer[indexA-1] = data; // keep input until DD
			//Stop UART Transmission.
			//Process Flag on.
		}
		else if (data == 0xDD)
		{
				final_pos = indexA -1;
				buffer[indexA-1] = data;
			//process the data.
			//of interupt UART,
				processData =1;
				indexA =0;
		}
		if(!(processData))
		{
		HAL_UART_Receive_IT(&huart1,&data, 1);
		}
}
/* USER CODE END 4 */

void _Error_Handler(char *file, int line)
{
  while(1)
  {
  }
}

/************************ (C) COPYRIGHT STMicroelectronics *****END OF FILE****/
